# STM32H743 register map
File version: 2.4
CPU: CM7 r0p1, little endian, MPU, FPU, 4 interrupt priority bits
Registers are 32-bit, read-write, reset 0x0 unless marked. A register's access mark holds for its fields unless they carry their own. Offsets are from the block's base; [hi:lo] are bit positions; {n}, {i} and the like mark numbered series; 'fields as' and 'values as' point back to an identical list.

## DMAMUX1 — DMAMUX（DMA 请求复用器）
Base 0x40020800
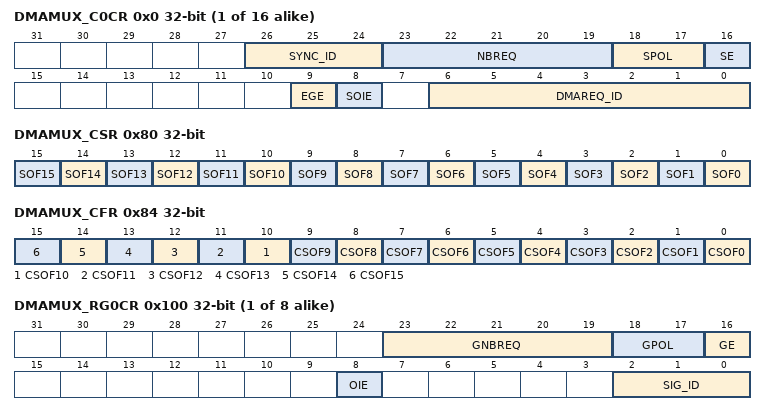
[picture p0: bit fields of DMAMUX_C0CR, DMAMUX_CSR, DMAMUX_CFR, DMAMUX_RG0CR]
{0x0+4i} DMAMUX_C{i}CR (i=0..15)
  [26:24] SYNC_ID — 同步信号识别。选择同步输入（参见输入与资源的映射关系）。
  [23:19] NBREQ — 待转发的 DMA 请求数减 1。定义同步事件后转发至 DMA 控制器的 DMA 请求数量，以及/或者生成输出事件前的 DMA 请求数量。此字段仅可在 SE 和 EGE 位均为低电平时写入。
  [18:17] SPOL — 同步极性。定义所选同步输入的边沿极性：
    0=无事件，即不进行同步也不进行检测。; 1=上升沿; 2=下降沿; 3=上升沿和下降沿
  [16] SE — 同步使能
    0=同步禁用; 1=同步使能
  [9] EGE — 事件生成使能
    0=事件生成禁用; 1=事件生成使能
  [8] SOIE — 同步溢出中断使能
    0=中断禁用; 1=中断使能
  [6:0] DMAREQ_ID — DMA 请求识别。选择输入 DMA 请求。关于复用器输入到资源的分配关系，请参阅 DMAMUX 表。
0x80 DMAMUX_CSR ro
  [n] SOF{n} (n=0..15) — 同步溢出事件标志。当 DMA 请求线复用器通道 x 上发生同步事件，且 DMA 请求计数器值低于 NBREQ 时，该标志位置位。通过向 DMAMUX_CFR 寄存器的对应 CSOFx 位写入 1 可清除此标志。对于 DMAMUX2，位 15:8 保留，请保持复位值。
0x84 DMAMUX_CFR wo
  [n] CSOF{n} (n=0..15) — 清除同步溢出事件标志。向每位写入 1 可清除 DMAMUX_CSR 寄存器中对应的溢出标志 SOFx。
{0x100+4i} DMAMUX_RG{i}CR (i=0..7)
  [23:19] GNBREQ — 待生成的 DMA 请求数（减 1）。定义触发事件后生成的 DMA 请求数量。实际生成的 DMA 请求数为 GNBREQ + 1。注意：此字段仅可在 GE 位禁用时写入。
  [18:17] GPOL — DMA 请求发生器触发极性。定义所选触发输入的边沿极性。
    0=无事件，即不进行触发检测也不生成触发。; 1=上升沿; 2=下降沿; 3=上升沿和下降沿
  [16] GE — DMA 请求发生器通道 x 使能
    0=DMA 请求发生器通道 x 禁用; 1=DMA 请求发生器通道 x 使能
  [8] OIE — 触发溢出中断使能
    0=触发溢出事件发生时中断禁用; 1=触发溢出事件发生时中断使能
  [2:0] SIG_ID — 信号识别。选择用于 DMA 请求发生器通道 x 的 DMA 请求触发输入。
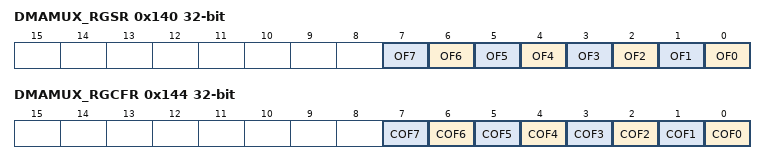
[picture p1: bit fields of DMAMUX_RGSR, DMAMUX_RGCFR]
0x140 DMAMUX_RGSR ro
  [n] OF{n} (n=0..7) — [:0]: 触发溢出事件标志。当 DMA 请求发生器通道 x 上发生新的触发事件，且发生在请求计数器下溢之前（内部请求计数器通过 DMAMUX_RGxCR 寄存器的 GNBREQ 字段编程设定），该标志位置位。通过向 DMAMUX_RGCFR 寄存器的对应 COFx 位写入 1 可清除此标志。
0x144 DMAMUX_RGCFR wo
  [n] COF{n} (n=0..7) — 清除触发溢出事件标志。向每位写入 1 可清除 DMAMUX_RGSR 寄存器中对应的溢出标志 OFx。

## DMAMUX2 — DMA 请求复用器
Base 0x58025800
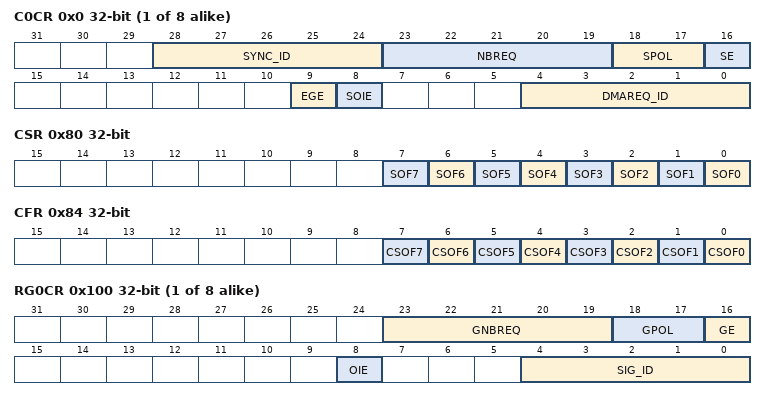
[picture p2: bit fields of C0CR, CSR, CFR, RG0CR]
{0x0+4i} C{i}CR (i=0..7) — DMA 请求线复用器通道 {i} 控制寄存器
  [28:24] SYNC_ID — 同步输入选择
  [23:19] NBREQ — DMA 请求转发数量。定义在产生输出事件之前转发的 DMA 请求数量。在同步模式下，该字段还定义了同步事件到来之后需要转发的 DMA 请求数量，达到该数量后停止转发。实际转发的 DMA 请求数量为 NBREQ+1。注意：仅当 SE 和 EGE 位均复位时才能写入此字段。
  [18:17] SPOL — 同步事件类型选择。定义所选同步输入上的同步事件：
  [16] SE — 同步工作模式使能/禁止
  [9] EGE — 事件生成使能/禁止
  [8] SOIE — 同步事件溢出中断使能
  [4:0] DMAREQ_ID — 输入 DMA 请求线选择
0x80 CSR ro
  [n] SOF{n} (n=0..7) — 同步溢出事件标志
0x84 CFR wo
  [n] CSOF{n} (n=0..7) — 清除同步溢出事件标志。向指定位写入 1 将清除 DMAMUX_CSR 寄存器中对应的溢出标志 SOFx。
{0x100+4i} RG{i}CR (i=0..7) — DMA 请求发生器通道 {i} 控制寄存器
  [23:19] GNBREQ — DMA 请求生成数量。定义触发事件到来之后生成的 DMA 请求数量，达到该数量后停止生成。实际生成的 DMA 请求数量为 GNBREQ+1。注意：仅当 GE 位复位时才能写入此字段。
  [18:17] GPOL — DMA 请求发生器触发事件类型选择。定义所选 DMA 请求触发输入上的触发事件。
  [16] GE — DMA 请求发生器通道使能/禁止
  [8] OIE — 触发事件溢出中断使能
  [4:0] SIG_ID — DMA 请求触发输入选择
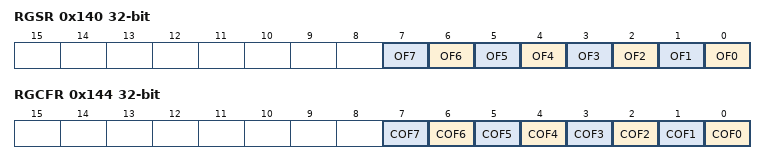
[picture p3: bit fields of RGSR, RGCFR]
0x140 RGSR ro
  [n] OF{n} (n=0..7) — 触发溢出事件标志
0x144 RGCFR ro
  [n] COF{n} (n=0..7) — 清除触发溢出事件标志

## HSEM — 硬件信号量（HSEM）
Base 0x58026400
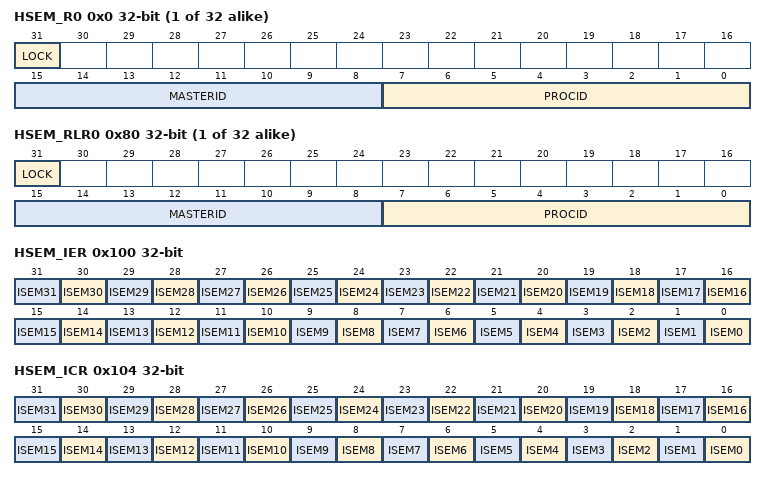
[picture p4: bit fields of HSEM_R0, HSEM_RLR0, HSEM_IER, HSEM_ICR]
{0x0+4i} HSEM_R{i} (i=0..31) — HSEM 寄存器
  [31] LOCK — 锁定指示
  [15:8] MASTERID — 信号量主设备 ID
  [7:0] PROCID — 信号量进程 ID
{0x80+4i} HSEM_RLR{i} ro (i=0..31) — HSEM 读锁定寄存器
  fields as HSEM_R0
0x100 HSEM_IER — HSEM 中断使能寄存器
  [n] ISEM{n} (n=0..31) — 信号量 n 中断使能位
0x104 HSEM_ICR ro — HSEM 中断清除寄存器
  [n] ISEM{n} (n=0..31) — 信号量 n 中断清除位
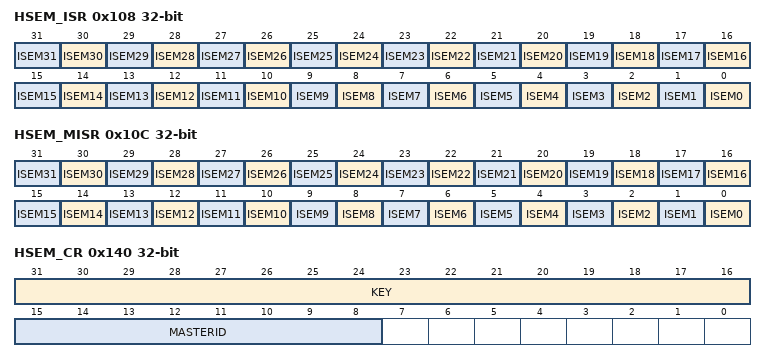
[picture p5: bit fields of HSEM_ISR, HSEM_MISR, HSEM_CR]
0x108 HSEM_ISR ro — HSEM 中断状态寄存器
  [n] ISEM{n} (n=0..31) — 信号量 n 中断状态位（使能屏蔽前）
0x10C HSEM_MISR ro — HSEM 屏蔽中断状态寄存器
  [n] ISEM{n} (n=0..31) — 信号量 n 中断状态位（使能屏蔽后）
0x140 HSEM_CR — HSEM 清除寄存器
  [31:16] KEY — 信号量清除密钥
  [15:8] MASTERID — 待清除信号量的主设备 ID
0x144 HSEM_KEYR — HSEM 密钥寄存器
  [31:16] KEY — 信号量清除密钥

## GPIOA — 通用输入输出端口
Base 0x58020000
Same registers: GPIOB 0x58020400, GPIOC 0x58020800, GPIOD 0x58020C00, GPIOE 0x58021000, GPIOF 0x58021400, GPIOG 0x58021800, GPIOH 0x58021C00, GPIOI 0x58022000, GPIOJ 0x58022400, GPIOK 0x58022800
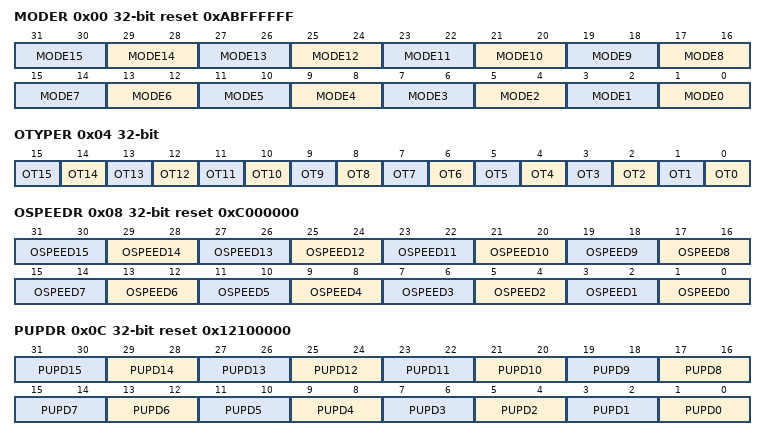
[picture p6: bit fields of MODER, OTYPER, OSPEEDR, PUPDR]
0x00 MODER reset 0xABFFFFFF — GPIO 端口模式寄存器
  [2n+1:2n] MODE{n} (n=0..15) — [1:0]：端口 x 配置位（y = 0..15）。由软件写入，用于配置 I/O 模式。
0x04 OTYPER — GPIO 端口输出类型寄存器
  [n] OT{n} (n=0..15) — 端口 x 配置位（y = 0..15）。由软件写入，用于配置 I/O 输出类型。
0x08 OSPEEDR reset 0xC000000 — GPIO 端口输出速度寄存器
  [2n+1:2n] OSPEED{n} (n=0..15) — [1:0]：端口 x 配置位（y = 0..15）。由软件写入，用于配置 I/O 输出速度。注意：各速度档位对应的频率规格及电源与负载条件，请参阅器件数据手册。
0x0C PUPDR reset 0x12100000 — GPIO 端口上拉/下拉寄存器
  [2n+1:2n] PUPD{n} (n=0..15) — [1:0]：端口 x 配置位（y = 0..15）。由软件写入，用于配置 I/O 上拉或下拉。
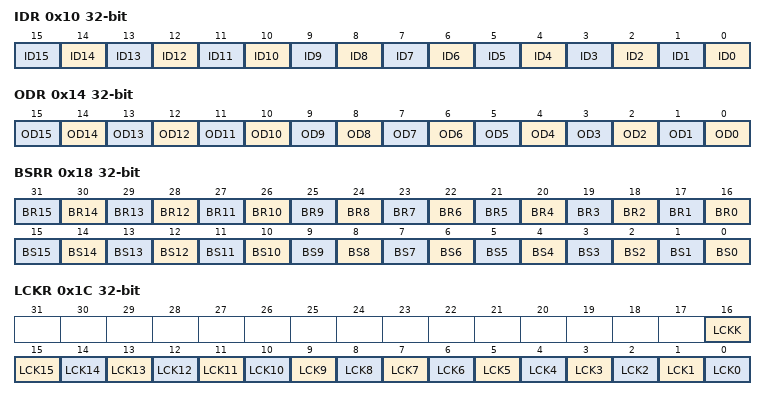
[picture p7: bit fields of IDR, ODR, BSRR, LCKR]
0x10 IDR ro — GPIO 端口输入数据寄存器
  [n] ID{n} (n=0..15) — 端口输入数据位（y = 0..15）。这些位为只读，保存对应 I/O 端口的输入值。
0x14 ODR — GPIO 端口输出数据寄存器
  [n] OD{n} (n=0..15) — 端口输出数据位。软件可读写这些位。注意：如需原子方式置位/复位，可通过写 GPIOx_BSRR 或 GPIOx_BRR 寄存器（x = A..F）来单独置位和/或复位各 OD 位。
0x18 BSRR wo — GPIO 端口置位/复位寄存器
  [n+16] BR{n} (n=0..15) — 端口 x 复位位 y（y = 0..15）。这些位为只写，读操作返回 0x0000。注意：若 BSx 和 BRx 同时置位，BSx 优先。
  [n] BS{n} (n=0..15) — 端口 x 置位位 y（y = 0..15）。这些位为只写，读操作返回 0x0000。
0x1C LCKR — 此寄存器用于在向位 16（LCKK）施加正确的写入序列后锁定端口位的配置。位 [15:0] 的值用于锁定 GPIO 的配置。写入序列期间，LCKR[15:0] 的值不得更改。在端口位上施加锁定序列后，该端口位的值将无法再被修改，直至下次 MCU 复位或外设复位。向 GPIOx_LCKR 寄存器写入需遵循特定的写入序列，锁定序列期间仅允许字访问（32 位）。每个锁定位将冻结对应的配置寄存器（控制寄存器和复用功能寄存器）。
  [16] LCKK — 锁定密钥。此位可随时读取，仅可通过锁定密钥写入序列进行修改。锁定密钥写入序列：WR LCKR[16] = 1 + LCKR[15:0]、WR LCKR[16] = 0 + LCKR[15:0]、WR LCKR[16] = 1 + LCKR[15:0]、RD LCKR、RD LCKR[16] = 1（此读操作为可选，但可用于确认锁定已生效）。注意：锁定密钥写入序列过程中，LCK[15:0] 的值不得更改。序列中任何错误都将导致本次锁定中止。在对端口的任意位成功执行首次锁定序列后，读取 LCKK 位将始终返回 1，直至下次 MCU 复位或外设复位。
  [n] LCK{n} (n=0..15) — 端口 x 锁定位 y（y = 0..15）。这些位可读写，但仅在 LCKK 位为 0 时可写。
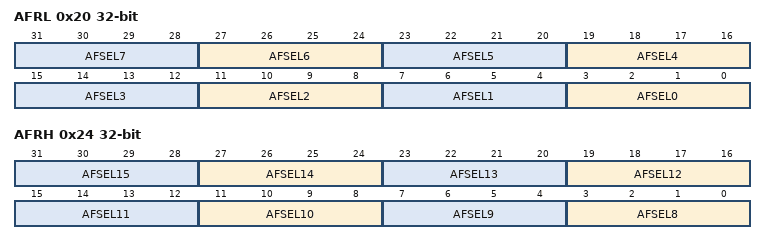
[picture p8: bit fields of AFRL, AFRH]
0x20 AFRL — GPIO 复用功能低位寄存器
  [4n+3:4n] AFSEL{n} (n=0..7) — [3:0]：端口 x 引脚 y 的复用功能选择（y = 0..7）。由软件写入，用于配置复用功能 I/O。AFSELy 选择：
0x24 AFRH — GPIO 复用功能高位寄存器
  [4n-29:4n-32] AFSEL{n} (n=8..15) — [3:0]：端口 x 引脚 y 的复用功能选择（y = 8..15）。由软件写入，用于配置复用功能 I/O。
